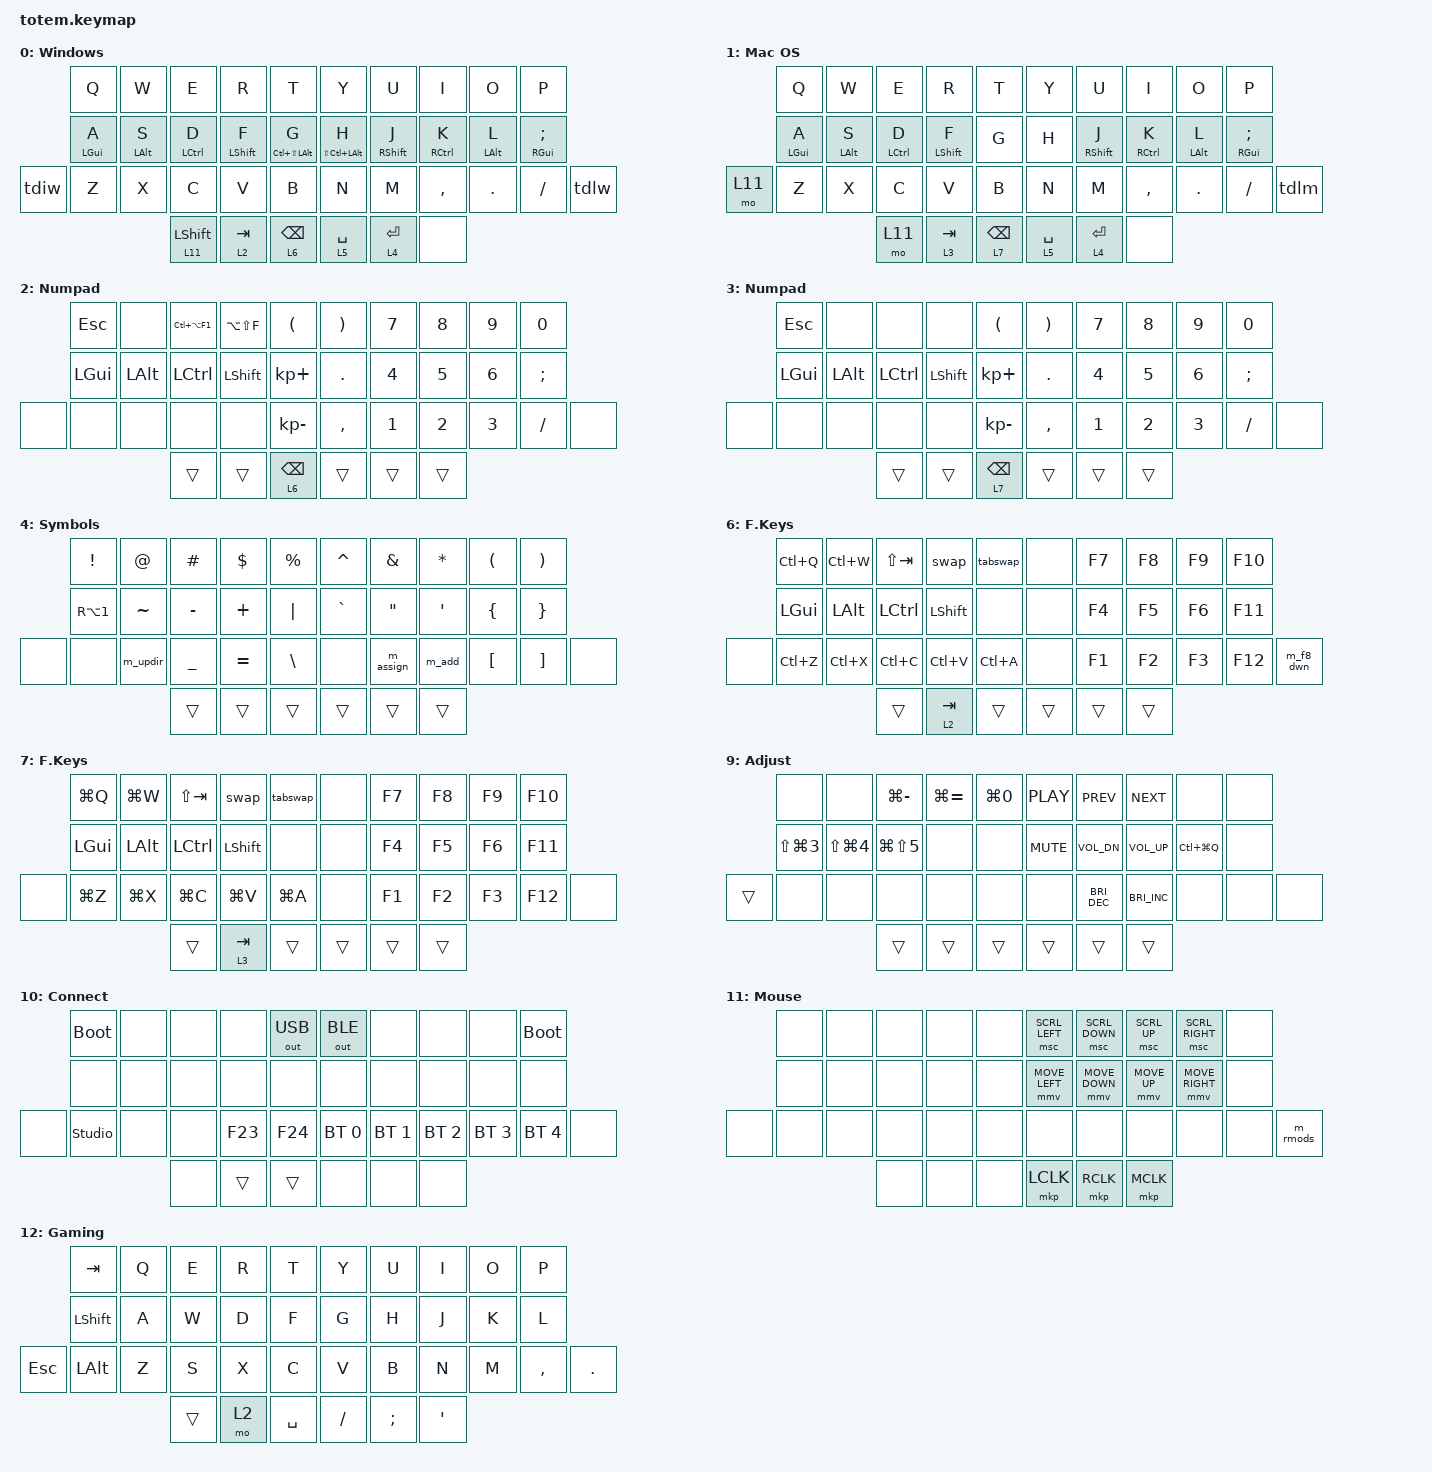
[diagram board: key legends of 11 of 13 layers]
//
//                                                        ▀▀▀▀▀     ▀▀▀▀▀          ▀▀█▀▀
//                                                        ▄▀▀▀▄  ▄  ▄▀▀▀▄  ▄  ▄▀▀▀▄  █  ▄▀▀▀▄
//                                                        █   █  █  █   █  █  █   █  █  █   █
//                                                         ▀▀▀   █   ▀▀▀   █   ▀▀▀   ▀   ▀▀▀
//                                                               █      ▄▄▄█▄▄▄    █   █
//                                                               ▀      █  █  █     █▄█
//                                                             ▀▀▀▀▀    █  █  █      ▀
//                                                                      ▀  ▀  ▀
//
// ▄▄▄▄▄▄▄▄▄▄▄▄▄▄▄▄▄▄▄▄▄▄▄▄▄▄▄▄▄▄▄▄▄▄▄▄▄▄▄▄▄▄▄▄▄▄▄▄▄▄▄▄▄▄▄▄▄▄▄▄▄▄▄▄▄▄▄▄▄▄▄▄▄▄▄▄▄▄▄▄▄▄▄▄▄▄▄▄▄▄▄▄▄▄▄▄▄▄▄▄▄▄▄▄▄▄▄▄▄▄▄▄▄▄▄▄▄▄▄▄▄▄▄▄▄▄▄▄▄▄▄▄▄▄▄▄▄▄▄▄▄▄▄▄▄▄▄▄▄

#include <behaviors.dtsi>
#include <dt-bindings/zmk/bt.h>
#include <dt-bindings/zmk/keys.h>
#include <dt-bindings/zmk/outputs.h>
#include <dt-bindings/zmk/pointing.h>

/ {
    behaviors {
        ht: hold_tap {
            label = "hold_tap";
            compatible = "zmk,behavior-hold-tap";
            #binding-cells = <2>;
            flavor = "tap-preferred";
            tapping-term-ms = <200>;
            quick-tap-ms = <0>;
            global-quick-tap;
            bindings = <&kp>, <&kp>;
        };

        pht: pinky_hold_tap {
            compatible = "zmk,behavior-hold-tap";
            label = "pinky_hold_tap";
            bindings = <&kp>, <&kp>;

            #binding-cells = <2>;
            tapping-term-ms = <300>;
            flavor = "tap-preferred";
            require-prior-idle-ms = <100>;
        };

        swap: swapper {
            compatible = "zmk,behavior-tri-state";
            label = "SWAPPER";
            #binding-cells = <0>;
            bindings = <&kt LALT>, <&kp TAB>, <&kt LALT>;

            ignored-key-positions = <0 1 2>;
            ignored-layers = <1>;
        };

        tabswap: tswapper {
            compatible = "zmk,behavior-tri-state";
            label = "TSWAPPER";
            #binding-cells = <0>;
            bindings = <&kt LCTRL>, <&kp TAB>, <&kt LCTRL>;

            ignored-key-positions = <2>;
            ignored-layers = <1>;
        };

        tdlw: tap_dance_lock_windows {
            compatible = "zmk,behavior-tap-dance";
            #binding-cells = <0>;
            tapping-term-ms = <250>;
            bindings = <&none>, <&none>, <&kp LG(L)>;
        };

        tdlm: tap_dance_lock_macos {
            compatible = "zmk,behavior-tap-dance";
            #binding-cells = <0>;
            tapping-term-ms = <250>;
            bindings =
                <&kp RC(RA(RG(RSHIFT)))>,
                <&kp LS(LA(LC(LG(F1))))>,
                <&kp LC(LG(Q))>;
        };

        tdiw: tap_dance_inspect_windows {
            compatible = "zmk,behavior-tap-dance";
            #binding-cells = <0>;
            bindings = <&mo 11>, <&kp LC(LA(F1))>;
        };
    };

    conditional_layers {
        compatible = "zmk,conditional-layers";

        Adjustment_Layer {
            if-layers = <2 4>;
            then-layer = <8>;
        };

        Adjustment_Mac {
            if-layers = <3 4>;
            then-layer = <9>;
        };

        Connection_Layter {
            if-layers = <2 6>;
            then-layer = <10>;
        };

        Connection_Mac {
            if-layers = <3 7>;
            then-layer = <10>;
        };
    };

    macros {
        m_updir: m_updir {
            compatible = "zmk,behavior-macro";
            #binding-cells = <0>;
            bindings = <&kp DOT &kp DOT &kp SLASH>;
            label = "M_UPDIR";
        };

        m_assign: m_assign {
            compatible = "zmk,behavior-macro";
            #binding-cells = <0>;
            bindings = <&kp COLON &kp EQUAL>;
            label = "M_ASSIGN";
        };

        m_add: m_add {
            compatible = "zmk,behavior-macro";
            #binding-cells = <0>;
            bindings = <&kp PLUS &kp EQUAL>;
            label = "M_ADD";
        };

        m_license: m_license {
            compatible = "zmk,behavior-macro";
            #binding-cells = <0>;
            bindings = <&kp LA(H) &kp L>, <&macro_wait_time 500>, <&kp LA(C)>;

            label = "M_LICENSE";
        };

        m_rmods: m_resmods {
            compatible = "zmk,behavior-macro";
            #binding-cells = <0>;
            bindings =
                <&macro_tap_time 50>,
                <&macro_wait_time 50>,
                <&kp LALT &kp LCTRL &kp LSHFT &kp RSHFT &kp RCTRL &kp RALT>;

            label = "M_RESMODS";
        };

        m_f8_dwn: m_f8_dwn {
            compatible = "zmk,behavior-macro";
            #binding-cells = <0>;
            bindings = <&kp F8 &kp DOWN>;
            label = "M_F8_DWN";
        };
    };

    combos {
        compatible = "zmk,combos";

        combo_esc_left {
            key-positions = <2 3>;
            bindings = <&kp ESC>;
            timeout-ms = <30>;
            layers = <0 1>;
        };

        combo_esc_right {
            bindings = <&kp ESCAPE>;
            key-positions = <6 7>;
            timeout-ms = <30>;
            layers = <0 1>;
        };

        combo_meet_mute {
            bindings = <&kp LC(D)>;
            key-positions = <27 28>;
            timeout-ms = <30>;
            layers = <0>;
        };

        combo_meet_cam {
            bindings = <&kp LC(E)>;
            key-positions = <28 29>;
            timeout-ms = <30>;
            layers = <0>;
        };

        combo_caps_word {
            bindings = <&caps_word>;
            key-positions = <13 16>;
            timeout-ms = <30>;
            layers = <0 1>;
        };

        combo_gaming {
            bindings = <&to 12>;
            key-positions = <30 31>;
            layers = <10>;
            timeout-ms = <30>;
        };

        combo_gaming_exit {
            bindings = <&to 0>;
            key-positions = <30 31>;
            layers = <11>;
            timeout-ms = <30>;
        };

        combo_cut_win {
            bindings = <&kp LC(X)>;
            key-positions = <21 22>;
            layers = <0>;
            timeout-ms = <30>;
        };

        combo_copy_win {
            bindings = <&kp LC(C)>;
            key-positions = <22 23>;
            layers = <0>;
            timeout-ms = <30>;
        };

        combo_paste_win {
            bindings = <&kp LC(V)>;
            key-positions = <23 24>;
            timeout-ms = <30>;
            layers = <0>;
        };

        combo_select_all_win {
            bindings = <&kp LC(A)>;
            key-positions = <24 25>;
            layers = <0>;
            timeout-ms = <30>;
        };

        combo_cut_mac {
            bindings = <&kp LG(X)>;
            key-positions = <21 22>;
            layers = <1>;
            timeout-ms = <30>;
        };

        combo_copy_mac {
            bindings = <&kp LG(C)>;
            key-positions = <22 23>;
            layers = <1>;
            timeout-ms = <30>;
        };

        combo_paste_mac {
            bindings = <&kp LG(V)>;
            key-positions = <23 24>;
            layers = <1>;
            timeout-ms = <30>;
        };

        combo_select_all_mac {
            bindings = <&kp LG(A)>;
            key-positions = <24 25>;
            layers = <1>;
            timeout-ms = <30>;
        };

        combo_win_switch {
            bindings = <&to 0>;
            key-positions = <21 0>;
            timeout-ms = <30>;
            layers = <0 1>;
        };

        combo_mac_switch {
            bindings = <&to 1>;
            key-positions = <30 9>;
            timeout-ms = <30>;
            layers = <0 1>;
        };

        combo_dongle_bootloader {
            bindings = <&bootloader>;
            key-positions = <21 22>;
            layers = <10>;
        };

        combo_ble_clear {
            bindings = <&bt BT_CLR>;
            key-positions = <5 6>;
            layers = <10>;
        };

        combo_ble_clear_all {
            bindings = <&bt BT_CLR_ALL>;
            key-positions = <9 5>;
            layers = <10>;
        };

        combo_lshift {
            bindings = <&kp LEFT_SHIFT>;
            key-positions = <13 14>;
            layers = <0 1>;
        };

        combo_rshift {
            bindings = <&kp RSHIFT>;
            key-positions = <16 15>;
            layers = <0 1>;
        };

        combo_bc_inspect {
            bindings = <&kp LA(LC(F1))>;
            key-positions = <4 5>;
            layers = <0>;
        };

        combo_chrome_devel {
            bindings = <&kp LC(LS(I))>;
            key-positions = <25 26>;
            layers = <0>;
        };
    };

    keymap {
        compatible = "zmk,keymap";

        Windows {
            label = "Windows";
            bindings = <
       &kp Q        &kp W       &kp E          &kp R        &kp T                  &kp Y                &kp U        &kp I        &kp O       &kp P
       &pht LGUI A  &ht LALT S  &ht LCTRL D    &ht LSHFT F  &pht LC(LS(LALT)) G    &pht LS(LC(LALT)) H  &ht RSHFT J  &ht RCTRL K  &ht LALT L  &pht RGUI SEMI
&tdiw  &kp Z        &kp X       &kp C          &kp V        &kp B                  &kp N                &kp M        &kp COMMA    &kp DOT     &kp FSLH        &tdlw
                                &lt 11 LSHIFT  &lt 2 TAB    &lt 6 BACKSPACE        &lt 5 SPACE          &lt 4 RET    &none
            >;
        };

        MacOS {
            label = "MacOS";
            display-name = "Mac OS";
            bindings = <
        &kp Q        &kp W       &kp E        &kp R        &kp T              &kp Y        &kp U        &kp I        &kp O       &kp P
        &pht LGUI A  &ht LALT S  &ht LCTRL D  &ht LSHFT F  &kp G              &kp H        &ht RSHFT J  &ht RCTRL K  &ht LALT L  &pht RGUI SEMI
&mo 11  &kp Z        &kp X       &kp C        &kp V        &kp B              &kp N        &kp M        &kp COMMA    &kp DOT     &kp FSLH        &tdlm
                                 &mo 11       &lt 3 TAB    &lt 7 BACKSPACE    &lt 5 SPACE  &lt 4 RET    &none
            >;
        };

        Numpad {
            display-name = "Numpad";
            bindings = <
       &kp ESC   &none     &kp LC(LA(F1))    &kp LA(LS(F))  &kp LEFT_PARENTHESIS    &kp RPAR    &kp NUMBER_7  &kp NUMBER_8  &kp NUMBER_9  &kp NUMBER_0
       &kp LGUI  &kp LALT  &kp LEFT_CONTROL  &kp LSHFT      &kp KP_PLUS             &kp PERIOD  &kp NUMBER_4  &kp NUMBER_5  &kp NUMBER_6  &kp SEMI
&none  &none     &none     &none             &none          &kp KP_MINUS            &kp COMMA   &kp NUMBER_1  &kp NUMBER_2  &kp NUMBER_3  &kp SLASH     &none
                           &trans            &trans         &lt 6 BSPC              &trans      &trans        &trans
            >;
        };

        Mac_Numpad {
            label = "Numpad";
            bindings = <
       &kp ESC   &none     &none             &none      &kp LEFT_PARENTHESIS    &kp RPAR    &kp NUMBER_7  &kp NUMBER_8  &kp NUMBER_9  &kp NUMBER_0
       &kp LGUI  &kp LALT  &kp LEFT_CONTROL  &kp LSHFT  &kp KP_PLUS             &kp PERIOD  &kp NUMBER_4  &kp NUMBER_5  &kp NUMBER_6  &kp SEMI
&none  &none     &none     &none             &none      &kp KP_MINUS            &kp COMMA   &kp NUMBER_1  &kp NUMBER_2  &kp NUMBER_3  &kp SLASH     &none
                           &trans            &trans     &lt 7 BSPC              &trans      &trans        &trans
            >;
        };

        Symbols {
            label = "Symbols";
            bindings = <
       &kp EXCL          &kp AT     &kp HASH   &kp DLLR   &kp PRCNT        &kp CARET  &kp AMPS           &kp ASTRK         &kp LEFT_PARENTHESIS  &kp RIGHT_PARENTHESIS
       &kp RA(NUMBER_1)  &kp TILDE  &kp MINUS  &kp PLUS   &kp PIPE         &kp GRAVE  &kp DOUBLE_QUOTES  &kp SINGLE_QUOTE  &kp LEFT_BRACE        &kp RIGHT_BRACE
&none  &none             &m_updir   &kp UNDER  &kp EQUAL  &kp BACKSLASH    &none      &m_assign          &m_add            &kp LEFT_BRACKET      &kp RIGHT_BRACKET      &none
                                    &trans     &trans     &trans           &trans     &trans             &trans
            >;
        };

        Navigation {
            label = "Navigate";
            display-name = "Navigate";
            bindings = <
       &kp RA(SEMICOLON)      &kp RA(GRAVE)  &kp RA(SQT)  &kp RA(NUMBER_6)       &kp RS(RA(SQT))     &kp HOME   &kp PAGE_DOWN  &kp PG_UP     &kp END    &none
       &kp LGUI               &kp LALT       &kp LCTRL    &kp LSHFT              &kp RA(NUMBER_1)    &kp LEFT   &kp DOWN       &kp UP_ARROW  &kp RIGHT  &none
&none  &kp RS(RA(SEMICOLON))  &kp RS(RA(C))  &kp RA(C)    &kp LS(LA(GRAVE))      &kp RA(SLASH)       &kp RA(N)  &kp RA(RS(N))  &none         &none      &none  &none
                                             &trans       &kp LC(LA(LG(SPACE)))  &kp DEL             &trans     &trans         &trans
            >;
        };

        FKeys {
            display-name = "F.Keys";
            bindings = <
       &kp LC(Q)  &kp LC(W)  &kp LS(TAB)  &swap           &tabswap     &none   &kp F7  &kp F8  &kp F9  &kp F10
       &kp LGUI   &kp LALT   &kp LCTRL    &kp LEFT_SHIFT  &none        &none   &kp F4  &kp F5  &kp F6  &kp F11
&none  &kp LC(Z)  &kp LC(X)  &kp LC(C)    &kp LC(V)       &kp LC(A)    &none   &kp F1  &kp F2  &kp F3  &kp F12  &m_f8_dwn
                             &trans       &lt 2 TAB       &trans       &trans  &trans  &trans
            >;
        };

        Mac_Fkeys {
            label = "FKeys";
            display-name = "F.Keys";
            bindings = <
       &kp LG(Q)  &kp LG(W)  &kp LS(TAB)  &swap           &tabswap     &none   &kp F7  &kp F8  &kp F9  &kp F10
       &kp LGUI   &kp LALT   &kp LCTRL    &kp LEFT_SHIFT  &none        &none   &kp F4  &kp F5  &kp F6  &kp F11
&none  &kp LG(Z)  &kp LG(X)  &kp LG(C)    &kp LG(V)       &kp LG(A)    &none   &kp F1  &kp F2  &kp F3  &kp F12  &none
                             &trans       &lt 3 TAB       &trans       &trans  &trans  &trans
            >;
        };

        Adjust {
            display-name = "Adjust";
            bindings = <
       &kp LC(LA(LS(LG(Q))))  &none                  &kp LC(MINUS)          &kp LC(EQUAL)          &kp LC(N0)               &kp C_PLAY        &kp C_PREV            &kp C_NEXT            &kp RG(NUMBER_4)            &kp RG(N5)
       &kp LS(LG(LA(LC(A))))  &kp LS(LA(LG(LC(S))))  &kp LG(LA(LS(LC(D))))  &kp LS(LC(LG(LA(F))))  &kp LS(LA(LC(LG(G))))    &kp C_MUTE        &kp C_VOL_DN          &kp C_VOLUME_UP       &m_license                  &kp LS(LG(LC(LA(SEMICOLON))))
&none  &kp LS(LA(LC(LG(Z))))  &kp LS(LA(LC(LG(X))))  &kp LS(LA(LC(LG(C))))  &kp LS(LA(LC(LG(V))))  &kp LS(LA(LC(LG(B))))    &kp RG(NUMBER_6)  &kp C_BRIGHTNESS_DEC  &kp C_BRIGHTNESS_INC  &kp LS(LA(LC(LG(PERIOD))))  &kp LA(LC(DEL))                &none
                                                     &trans                 &trans                 &trans                   &trans            &trans                &trans
            >;
        };

        Mac_Adjust {
            label = "Adjust";
            display-name = "Adjust";
            bindings = <
        &none                 &none           &kp LG(MINUS)   &kp LG(EQUAL)  &kp LG(N0)    &kp C_PLAY  &kp C_PREV            &kp C_NEXT            &none          &none
        &kp LS(LG(NUMBER_3))  &kp LS(LG(N4))  &kp LG(LS(N5))  &none          &none         &kp C_MUTE  &kp C_VOL_DN          &kp C_VOLUME_UP       &kp LC(LG(Q))  &none
&trans  &none                 &none           &none           &none          &none         &none       &kp C_BRIGHTNESS_DEC  &kp C_BRIGHTNESS_INC  &none          &none  &none
                                              &trans          &trans         &trans        &trans      &trans                &trans
            >;
        };

        Connectivity {
            label = "Connect";
            display-name = "Connect";
            bindings = <
       &bootloader     &none  &none  &none    &out OUT_USB    &out OUT_BLE  &none         &none         &none         &bootloader
       &none           &none  &none  &none    &none           &none         &none         &none         &none         &none
&none  &studio_unlock  &none  &none  &kp F23  &kp F24         &bt BT_SEL 0  &bt BT_SEL 1  &bt BT_SEL 2  &bt BT_SEL 3  &bt BT_SEL 4  &none
                              &none  &trans   &trans          &none         &none         &none
            >;
        };

        Mouse {
            label = "Mouse";
            bindings = <
       &none  &none  &none  &none  &none    &msc SCRL_LEFT  &msc SCRL_DOWN  &msc SCRL_UP  &msc SCRL_RIGHT  &none
       &none  &none  &none  &none  &none    &mmv MOVE_LEFT  &mmv MOVE_DOWN  &mmv MOVE_UP  &mmv MOVE_RIGHT  &none
&none  &none  &none  &none  &none  &none    &none           &none           &none         &none            &none  &m_rmods
                     &none  &none  &none    &mkp LCLK       &mkp RCLK       &mkp MCLK
            >;
        };

        Gaming {
            label = "Gaming";
            display-name = "Gaming";
            bindings = <
         &kp TAB    &kp Q  &kp E   &kp R  &kp T        &kp Y     &kp U     &kp I     &kp O  &kp P
         &kp LSHFT  &kp A  &kp W   &kp D  &kp F        &kp G     &kp H     &kp J     &kp K  &kp L
&kp ESC  &kp LALT   &kp Z  &kp S   &kp X  &kp C        &kp V     &kp B     &kp N     &kp M  &kp COMMA  &kp DOT
                           &trans  &mo 2  &kp SPACE    &kp FSLH  &kp SEMI  &kp APOS
            >;
        };
    };
};
